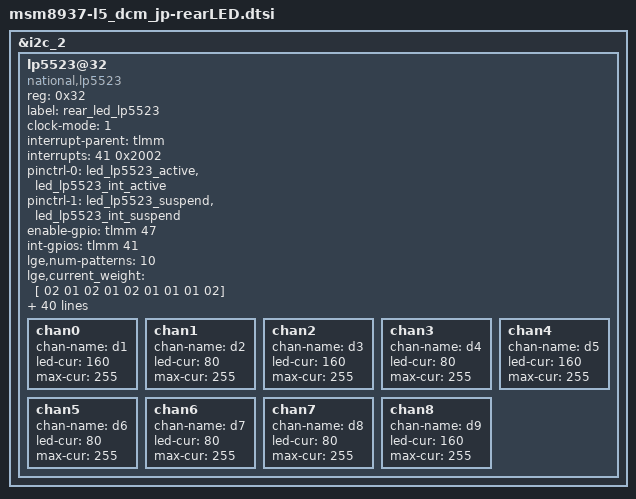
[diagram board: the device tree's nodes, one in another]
/*
 * Copyright (c) 2015, The Linux Foundation. All rights reserved.
 *
 * This program is free software; you can redistribute it and/or modify
 * it under the terms of the GNU General Public License version 2 and
 * only version 2 as published by the Free Software Foundation.
 *
 * This program is distributed in the hope that it will be useful,
 * but WITHOUT ANY WARRANTY; without even the implied warranty of
 * MERCHANTABILITY or FITNESS FOR A PARTICULAR PURPOSE.  See the
 * GNU General Public License for more details.
 */
&i2c_2 { /* BLSP1 QUP2 */
	status = "ok";

	lp5523@32 {
		compatible = "national,lp5523";
		reg = <0x32>;
		label = "rear_led_lp5523";
		clock-mode = /bits/8 <1>;

		interrupt-parent = <&tlmm>;
		interrupts = <41 0x2002>; /*IRQF_ONESHOT | IRQF_TRIGGER_FALLING*/

		pinctrl-names = "led_pin_active","led_pin_sleep";   /*LED GPIO pin name setting*/
		pinctrl-0 = <&led_lp5523_active &led_lp5523_int_active>;      /*LED GPIO pin active setting*/
		pinctrl-1 = <&led_lp5523_suspend &led_lp5523_int_suspend>;      /*LED GPIO pin suspend setting*/

		enable-gpio = <&tlmm 47 0>;
		int-gpios = <&tlmm 41 0x2000>; /*IRQF_ONESHOT | IRQF_TRIGGER_FALLING*/

		lge,num-patterns = /bits/8 <10>;
		lge,current_weight = [ 02 01 02 01 02 01 01 01 02]; // LED 1, 3, 5, 9 are 2 channel
		lge,pattern-idx-1 = /bits/8 <107>; /* pattern 107 : unlock */
		lge,start_addr-1 = [05 14 15];
		lge,pattern-1 = [
			00 20 00 04 00 CA 01 11 01 FF 9C 00 9C 84 9C 00
			02 FF 9D 80 02 FF 9D 80 02 FF 9D 80 02 FF 9D 80
			4C 00 03 FF D0 00 00 00 00 00 00 00 00 00 00 00
			00 00 00 00 00 00 00 00 00 00 00 00 00 00 00 00
			00 00 00 00 00 00 00 00 00 00 00 00 00 00 00 00
			00 00 00 00 00 00 00 00 00 00 00 00 00 00 00 00
			00 00 00 00 00 00 00 00 00 00 00 00 00 00 00 00
			00 00 00 00 00 00 00 00 00 00 00 00 00 00 00 00
			00 00 00 00 00 00 00 00 00 00 00 00 00 00 00 00
			00 00 00 00 00 00 00 00 00 00 00 00 00 00 00 00
			00 00 00 00 00 00 00 00 00 00 00 00 00 00 00 00
			00 00 00 00 00 00 00 00 00 00 00 00 00 00 00 00
			];

		lge,pattern-idx-2 = /bits/8 <1>; /* pattern 1 : Power on*/
		lge,start_addr-2 = [05 17 18];
		lge,pattern-2 = [
			00 20 00 04 00 CA 01 11 01 FF 9C 00 9C 84 9C 00
			02 FF 9D 80 02 FF 9D 80 02 FF 9D 80 02 FF 9D 80
			7E 00 7E 00 11 7F 11 80 40 00 D0 00 00 00 00 00
			00 00 00 00 00 00 00 00 00 00 00 00 00 00 00 00
			00 00 00 00 00 00 00 00 00 00 00 00 00 00 00 00
			00 00 00 00 00 00 00 00 00 00 00 00 00 00 00 00
			00 00 00 00 00 00 00 00 00 00 00 00 00 00 00 00
			00 00 00 00 00 00 00 00 00 00 00 00 00 00 00 00
			00 00 00 00 00 00 00 00 00 00 00 00 00 00 00 00
			00 00 00 00 00 00 00 00 00 00 00 00 00 00 00 00
			00 00 00 00 00 00 00 00 00 00 00 00 00 00 00 00
			00 00 00 00 00 00 00 00 00 00 00 00 00 00 00 00
			];

		lge,pattern-idx-3 = /bits/8 <3>; /* pattern 3 : start charging*/
		lge,start_addr-3 = [05 1B 1C];
		lge,pattern-3 = [
			00 20 00 04 00 CA 01 11 01 FF 9C 00 9C 84 9C 00
			02 FF 9D 80 02 FF 9D 80 02 FF 9D 80 02 FF 9D 80
			7E 00 9D C0 03 FF 9D C0 03 FF 9D C0 03 FF 9D C0
			03 FF D0 00 00 00 00 00 00 00 00 00 00 00 00 00
			00 00 00 00 00 00 00 00 00 00 00 00 00 00 00 00
			00 00 00 00 00 00 00 00 00 00 00 00 00 00 00 00
			00 00 00 00 00 00 00 00 00 00 00 00 00 00 00 00
			00 00 00 00 00 00 00 00 00 00 00 00 00 00 00 00
			00 00 00 00 00 00 00 00 00 00 00 00 00 00 00 00
			00 00 00 00 00 00 00 00 00 00 00 00 00 00 00 00
			00 00 00 00 00 00 00 00 00 00 00 00 00 00 00 00
			00 00 00 00 00 00 00 00 00 00 00 00 00 00 00 00
			];
		lge,pattern-idx-4 = /bits/8 <108>;  /* pattern 108 : Incoming call */
		lge,start_addr-4 = [04 0F 19];
		lge,pattern-4 = [
			00 08 00 D6 01 21 01 FF 9C 00 9C 83 E2 00 9C 00
			04 55 E0 04 04 AA 9D 00 A0 02 00 00 00 00 9C 01
			9C 83 E0 80 9C 01 04 55 E0 08 04 AA 9D 00 A0 02
			00 00 9C 02 9C 83 90 03 94 00 92 01 E0 02 E1 00
			04 FF 88 41 7E 00 9D 80 05 FF 9D C0 5A 00 9D 80
			40 00 9D C0 A1 04 7E 00 A0 02 00 00 00 00 00 00
			00 00 00 00 00 00 00 00 00 00 00 00 00 00 00 00
			00 00 00 00 00 00 00 00 00 00 00 00 00 00 00 00
			00 00 00 00 00 00 00 00 00 00 00 00 00 00 00 00
			00 00 00 00 00 00 00 00 00 00 00 00 00 00 00 00
			00 00 00 00 00 00 00 00 00 00 00 00 00 00 00 00
			00 00 00 00 00 00 00 00 00 00 00 00 00 00 00 00
			];

		lge,pattern-idx-5 = /bits/8 <109>;  /* pattern 109 : Disney kisekae alarm */
		lge,start_addr-5 = [04 0F 19];
		lge,pattern-5 = [
			00 08 00 D6 01 21 01 FF 9C 00 9C 83 E2 00 9C 00
			04 55 E0 04 04 AA 9D 00 A0 02 00 00 00 00 9C 01
			9C 83 E0 80 9C 01 04 55 E0 08 04 AA 9D 00 A0 02
			00 00 9C 02 9C 83 90 0C 94 00 92 01 E0 02 E1 00
			04 FF 9D 80 88 31 7E 00 7E 00 05 FF 66 00 40 00
			9D C0 4C 00 A5 84 D0 00 00 00 00 00 00 00 00 00
			00 00 00 00 00 00 00 00 00 00 00 00 00 00 00 00
			00 00 00 00 00 00 00 00 00 00 00 00 00 00 00 00
			00 00 00 00 00 00 00 00 00 00 00 00 00 00 00 00
			00 00 00 00 00 00 00 00 00 00 00 00 00 00 00 00
			00 00 00 00 00 00 00 00 00 00 00 00 00 00 00 00
			00 00 00 00 00 00 00 00 00 00 00 00 00 00 00 00
			];

		lge,pattern-idx-6 = /bits/8 <110>;  /* pattern 110 : Receiving DOCOMO mail & SMS & Disney market Push Noti. 2-4-6 */
		lge,start_addr-6 = [04 0F 19];
		lge,pattern-6 = [
			00 08 00 D6 01 21 01 FF 9C 00 9C 83 E2 00 9C 00
			08 55 E0 04 08 AA 9D 00 A0 02 00 00 00 00 9C 01
			9C 83 E0 80 9C 01 08 55 E0 08 08 AA 9D 00 A0 02
			00 00 9C 02 9C 83 90 04 94 00 92 01 E0 02 E1 00
			08 FF 9D 80 8E 41 05 FF 9D C0 54 00 A1 84 4C 00
			05 FF D0 00 00 00 00 00 00 00 00 00 00 00 00 00
			00 00 00 00 00 00 00 00 00 00 00 00 00 00 00 00
			00 00 00 00 00 00 00 00 00 00 00 00 00 00 00 00
			00 00 00 00 00 00 00 00 00 00 00 00 00 00 00 00
			00 00 00 00 00 00 00 00 00 00 00 00 00 00 00 00
			00 00 00 00 00 00 00 00 00 00 00 00 00 00 00 00
			00 00 00 00 00 00 00 00 00 00 00 00 00 00 00 00
			];

		lge,pattern-idx-7 = /bits/8 <111>;  /* pattern 111 : camera timer  3S */
		lge,start_addr-7 = [01 12 13];
		lge,pattern-7 = [
			01 FF 9D 00 9C 00 40 FF 5A 00 40 00 66 00 A1 82
			40 FF 54 00 40 00 5A 00 40 FF 54 00 40 00 4C 00
			A1 0B D0 00 00 00 00 00 00 00 00 00 00 00 00 00
			00 00 00 00 00 00 00 00 00 00 00 00 00 00 00 00
			00 00 00 00 00 00 00 00 00 00 00 00 00 00 00 00
			00 00 00 00 00 00 00 00 00 00 00 00 00 00 00 00
			00 00 00 00 00 00 00 00 00 00 00 00 00 00 00 00
			00 00 00 00 00 00 00 00 00 00 00 00 00 00 00 00
			00 00 00 00 00 00 00 00 00 00 00 00 00 00 00 00
			00 00 00 00 00 00 00 00 00 00 00 00 00 00 00 00
			00 00 00 00 00 00 00 00 00 00 00 00 00 00 00 00
			00 00 00 00 00 00 00 00 00 00 00 00 00 00 00 00
			];

		lge,pattern-idx-8 = /bits/8 <112>;  /* pattern 112 : camera timer  7S */
		lge,start_addr-8 = [01 19 1A];
		lge,pattern-8 = [
			01 FF 9D 00 9C 00 40 FF 66 00 40 00 5A 00 66 00
			5A 00 A1 82 40 FF 5A 00 40 00 66 00 A1 89 40 FF
			5A 00 40 00 54 00 40 FF 54 00 40 00 4C 00 A1 12
			D0 00 00 00 00 00 00 00 00 00 00 00 00 00 00 00
			00 00 00 00 00 00 00 00 00 00 00 00 00 00 00 00
			00 00 00 00 00 00 00 00 00 00 00 00 00 00 00 00
			00 00 00 00 00 00 00 00 00 00 00 00 00 00 00 00
			00 00 00 00 00 00 00 00 00 00 00 00 00 00 00 00
			00 00 00 00 00 00 00 00 00 00 00 00 00 00 00 00
			00 00 00 00 00 00 00 00 00 00 00 00 00 00 00 00
			00 00 00 00 00 00 00 00 00 00 00 00 00 00 00 00
			00 00 00 00 00 00 00 00 00 00 00 00 00 00 00 00
			];

		lge,pattern-idx-9 = /bits/8 <113>;  /* pattern 113 : camera timer 10S */
		lge,start_addr-9 = [01 19 1A];
		lge,pattern-9 = [
			01 FF 9D 00 9C 00 40 FF 66 00 40 00 5A 00 66 00
			5A 00 A3 02 40 FF 5A 00 40 00 66 00 A1 89 40 FF
			5A 00 40 00 54 00 40 FF 54 00 40 00 4C 00 A1 12
			D0 00 00 00 00 00 00 00 00 00 00 00 00 00 00 00
			00 00 00 00 00 00 00 00 00 00 00 00 00 00 00 00
			00 00 00 00 00 00 00 00 00 00 00 00 00 00 00 00
			00 00 00 00 00 00 00 00 00 00 00 00 00 00 00 00
			00 00 00 00 00 00 00 00 00 00 00 00 00 00 00 00
			00 00 00 00 00 00 00 00 00 00 00 00 00 00 00 00
			00 00 00 00 00 00 00 00 00 00 00 00 00 00 00 00
			00 00 00 00 00 00 00 00 00 00 00 00 00 00 00 00
			00 00 00 00 00 00 00 00 00 00 00 00 00 00 00 00
			];

		lge,pattern-idx-10 = /bits/8 <115>;  /* pattern 115 : welcome Apps */
		lge,start_addr-10 = [04 0F 19];
		lge,pattern-10 = [
			00 08 00 D6 01 21 01 FF 9C 00 9C 83 E2 00 9C 00
			08 55 E0 04 08 AA 9D 00 A0 02 00 00 00 00 9C 01
			9C 83 E0 80 9C 01 08 55 E0 08 08 AA 9D 00 A0 02
			00 00 9C 02 9C 83 90 08 94 00 92 01 E0 02 E1 00
			08 FF 9D 80 8E 41 05 FF 9D C0 54 00 A3 84 4C 00
			05 FF D0 00 00 00 00 00 00 00 00 00 00 00 00 00
			00 00 00 00 00 00 00 00 00 00 00 00 00 00 00 00
			00 00 00 00 00 00 00 00 00 00 00 00 00 00 00 00
			00 00 00 00 00 00 00 00 00 00 00 00 00 00 00 00
			00 00 00 00 00 00 00 00 00 00 00 00 00 00 00 00
			00 00 00 00 00 00 00 00 00 00 00 00 00 00 00 00
			00 00 00 00 00 00 00 00 00 00 00 00 00 00 00 00
			];

		chan0 {
			chan-name = "d1";
			led-cur = /bits/ 8 <160>; /* 2 chanel */
			max-cur = /bits/ 8 <255>;
		};
		chan1 {
			chan-name = "d2";
			led-cur = /bits/ 8 <80>;
			max-cur = /bits/ 8 <255>;
		};
		chan2 {
			chan-name = "d3";
			led-cur = /bits/ 8 <160>; /* 2 chanel */
			max-cur = /bits/ 8 <255>;
		};
		chan3 {
			chan-name = "d4";
			led-cur = /bits/ 8 <80>;
			max-cur = /bits/ 8 <255>;
		};
		chan4 {
			chan-name = "d5";
			led-cur = /bits/ 8 <160>; /* 2 chanel */
			max-cur = /bits/ 8 <255>;
		};
		chan5 {
			chan-name = "d6";
			led-cur = /bits/ 8 <80>;
			max-cur = /bits/ 8 <255>;
		};
		chan6 {
			chan-name = "d7";
			led-cur = /bits/ 8 <80>;
			max-cur = /bits/ 8 <255>;
		};
		chan7 {
			chan-name = "d8";
			led-cur = /bits/ 8 <80>;
			max-cur = /bits/ 8 <255>;
		};
		chan8 {
			chan-name = "d9";
			led-cur = /bits/ 8 <160>; /* 2 chanel */
			max-cur = /bits/ 8 <255>;
		};
	};
};
